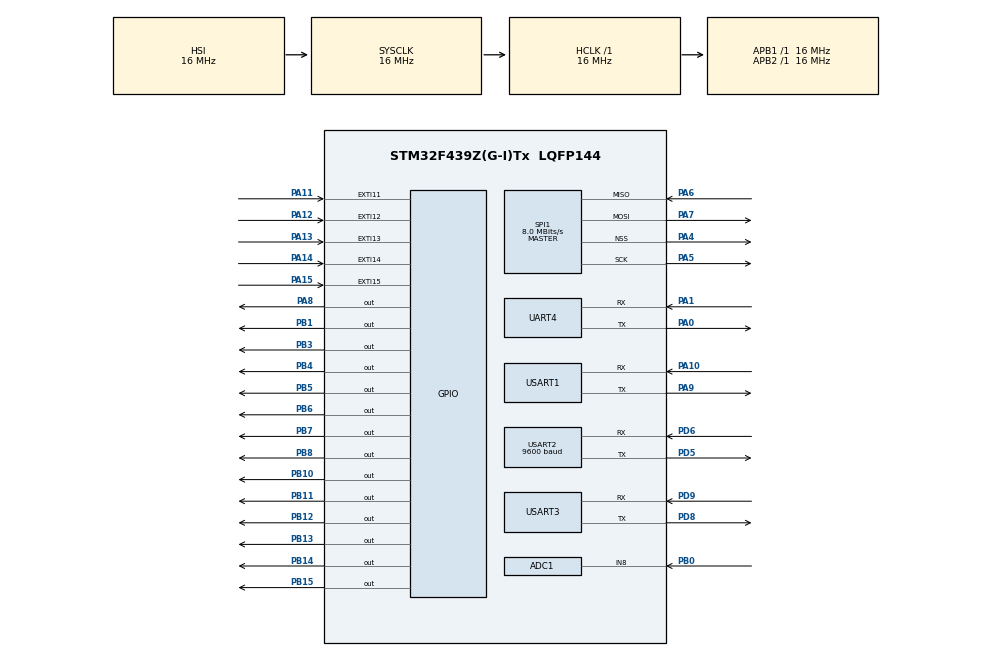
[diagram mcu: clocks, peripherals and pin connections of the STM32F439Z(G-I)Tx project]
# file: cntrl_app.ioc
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ADC1.Channel-0\#ChannelRegularConversion=ADC_CHANNEL_VBAT
ADC1.Channel-1\#ChannelRegularConversion=ADC_CHANNEL_8
ADC1.EOCSelection=ADC_EOC_SINGLE_CONV
ADC1.EnableAnalogWatchDog=false
ADC1.InjNumberOfConversion=0
ADC1.NbrOfConversion=2
ADC1.NbrOfConversionFlag=1
ADC1.Rank-0\#ChannelRegularConversion=1
ADC1.Rank-1\#ChannelRegularConversion=2
ADC1.SamplingTime-0\#ChannelRegularConversion=ADC_SAMPLETIME_3CYCLES
ADC1.SamplingTime-1\#ChannelRegularConversion=ADC_SAMPLETIME_3CYCLES
ADC1.master=1
Dma.Request0=SPI1_TX
Dma.Request1=SPI1_RX
Dma.SPI1_RX.1.Direction=DMA_PERIPH_TO_MEMORY
Dma.SPI1_RX.1.FIFOMode=DMA_FIFOMODE_ENABLE
Dma.SPI1_RX.1.FIFOThreshold=DMA_FIFO_THRESHOLD_FULL
Dma.SPI1_RX.1.Instance=DMA2_Stream0
Dma.SPI1_RX.1.MemBurst=DMA_MBURST_SINGLE
Dma.SPI1_RX.1.MemDataAlignment=DMA_MDATAALIGN_BYTE
Dma.SPI1_RX.1.MemInc=DMA_MINC_ENABLE
Dma.SPI1_RX.1.Mode=DMA_NORMAL
Dma.SPI1_RX.1.PeriphBurst=DMA_PBURST_SINGLE
Dma.SPI1_RX.1.PeriphDataAlignment=DMA_PDATAALIGN_BYTE
Dma.SPI1_RX.1.PeriphInc=DMA_PINC_DISABLE
Dma.SPI1_RX.1.Priority=DMA_PRIORITY_LOW
Dma.SPI1_TX.0.Direction=DMA_MEMORY_TO_PERIPH
Dma.SPI1_TX.0.FIFOMode=DMA_FIFOMODE_ENABLE
Dma.SPI1_TX.0.FIFOThreshold=DMA_FIFO_THRESHOLD_FULL
Dma.SPI1_TX.0.Instance=DMA2_Stream3
Dma.SPI1_TX.0.MemBurst=DMA_MBURST_SINGLE
Dma.SPI1_TX.0.MemDataAlignment=DMA_MDATAALIGN_BYTE
Dma.SPI1_TX.0.MemInc=DMA_MINC_ENABLE
Dma.SPI1_TX.0.Mode=DMA_NORMAL
Dma.SPI1_TX.0.PeriphBurst=DMA_PBURST_SINGLE
Dma.SPI1_TX.0.PeriphDataAlignment=DMA_PDATAALIGN_BYTE
Dma.SPI1_TX.0.PeriphInc=DMA_PINC_DISABLE
Dma.SPI1_TX.0.Priority=DMA_PRIORITY_LOW
Mcu.Family=STM32F4
Mcu.Name=STM32F439Z(G-I)Tx
Mcu.Package=LQFP144
NVIC.DMA2_Stream0_IRQn=true\:1\:0\:true\:false\:true\:false\:true
NVIC.DMA2_Stream3_IRQn=true\:1\:0\:true\:false\:true\:false\:true
NVIC.EXTI15_10_IRQn=true\:1\:0\:true\:false\:true\:true\:true
NVIC.PriorityGroup=NVIC_PRIORITYGROUP_4
NVIC.RTC_Alarm_IRQn=true\:1\:0\:true\:false\:true\:true\:true
NVIC.UART4_IRQn=true\:0\:0\:false\:false\:true\:true\:true
NVIC.USART2_IRQn=true\:0\:0\:true\:false\:true\:true\:true
PA0/WKUP.Mode=Asynchronous
PA0/WKUP.Signal=UART4_TX
PA1.Mode=Asynchronous
PA1.Signal=UART4_RX
PA10.Mode=Asynchronous
PA10.Signal=USART1_RX
PA11.GPIO_ModeDefaultEXTI=GPIO_MODE_IT_RISING_FALLING
PA11.Signal=GPXTI11
PA12.GPIO_ModeDefaultEXTI=GPIO_MODE_IT_RISING_FALLING
PA12.Signal=GPXTI12
PA13.GPIO_ModeDefaultEXTI=GPIO_MODE_IT_RISING_FALLING
PA13.Signal=GPXTI13
PA14.GPIO_ModeDefaultEXTI=GPIO_MODE_IT_RISING_FALLING
PA14.Signal=GPXTI14
PA15.GPIO_ModeDefaultEXTI=GPIO_MODE_IT_RISING_FALLING
PA15.Signal=GPXTI15
PA4.GPIO_PuPd=GPIO_PULLUP
PA4.GPIO_Speed=GPIO_SPEED_FREQ_VERY_HIGH
PA4.Mode=NSS_Signal_Hard_Output
PA4.Signal=SPI1_NSS
PA5.GPIO_Speed=GPIO_SPEED_FREQ_VERY_HIGH
PA5.Mode=Full_Duplex_Master
PA5.Signal=SPI1_SCK
PA6.Mode=Full_Duplex_Master
PA6.Signal=SPI1_MISO
PA7.Mode=Full_Duplex_Master
PA7.Signal=SPI1_MOSI
PA8.Signal=GPIO_Output
PA9.Mode=Asynchronous
PA9.Signal=USART1_TX
PB0.Signal=ADCx_IN8
PB1.Signal=GPIO_Output
PB10.Signal=GPIO_Output
PB11.Signal=GPIO_Output
PB12.Signal=GPIO_Output
PB13.Signal=GPIO_Output
PB14.Signal=GPIO_Output
PB15.Signal=GPIO_Output
PB3.Signal=GPIO_Output
PB4.Signal=GPIO_Output
PB5.Signal=GPIO_Output
PB6.Signal=GPIO_Output
PB7.Signal=GPIO_Output
PB8.Signal=GPIO_Output
PC14/OSC32_IN.Mode=LSE-External-Oscillator
PC14/OSC32_IN.Signal=RCC_OSC32_IN
PC15/OSC32_OUT.Mode=LSE-External-Oscillator
PC15/OSC32_OUT.Signal=RCC_OSC32_OUT
PD5.Mode=Asynchronous
PD5.Signal=USART2_TX
PD6.Mode=Asynchronous
PD6.Signal=USART2_RX
PD8.Mode=Asynchronous
PD8.Signal=USART3_TX
PD9.Mode=Asynchronous
PD9.Signal=USART3_RX
ProjectManager.HeapSize=0x200
ProjectManager.StackSize=0x400
ProjectManager.TargetToolchain=STM32CubeIDE
RCC.AHBFreq_Value=16000000
RCC.APB1Freq_Value=16000000
RCC.APB2Freq_Value=16000000
RCC.CortexFreq_Value=16000000
RCC.HSE_VALUE=25000000
RCC.HSI_VALUE=16000000
RCC.RCC_RTC_Clock_Source=RCC_RTCCLKSOURCE_LSE
RCC.RCC_RTC_Clock_SourceVirtual=RCC_RTCCLKSOURCE_LSE
RCC.SYSCLKFreq_VALUE=16000000
RCC.VCOOutputFreq_Value=192000000
RTC.Alarm=RTC_ALARM_A
RTC.Alarm_B=RTC_ALARM_B
SH.ADCx_IN8.0=ADC1_IN8,IN8
SPI1.BaudRatePrescaler=SPI_BAUDRATEPRESCALER_2
SPI1.CalculateBaudRate=8.0 MBits/s
SPI1.Direction=SPI_DIRECTION_2LINES
SPI1.Mode=SPI_MODE_MASTER
SPI1.VirtualNSS=VM_NSSHARD
SPI1.VirtualType=VM_MASTER
UART4.VirtualMode=Asynchronous
USART1.VirtualMode=VM_ASYNC
USART2.BaudRate=9600
USART2.VirtualMode=VM_ASYNC
USART3.VirtualMode=VM_ASYNC
VP_ADC1_Vbat_Input.Mode=IN-Vbat
VP_RTC_VS_RTC_Activate.Mode=RTC_Enabled
VP_RTC_VS_RTC_Alarm_A_Intern.Mode=Alarm A
VP_RTC_VS_RTC_Alarm_B_Intern.Mode=Alarm B
VP_RTC_VS_RTC_Calendar.Mode=RTC_Calendar
board=custom

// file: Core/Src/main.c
/* USER CODE BEGIN Header */
/**
  ******************************************************************************
  * @file           : main.c
  * @brief          : Main program body
  ******************************************************************************
  * @attention
  *
  * <h2><center>&copy; Copyright (c) 2020 STMicroelectronics.
  * All rights reserved.</center></h2>
  *
  * This software component is licensed by ST under BSD 3-Clause license,
  * the "License"; You may not use this file except in compliance with the
  * License. You may obtain a copy of the License at:
  *                        opensource.org/licenses/BSD-3-Clause
  *
  ******************************************************************************
  */
/* USER CODE END Header */

#include "main.h"

/* USER CODE BEGIN Includes */
#include "app.h"

/* USER CODE END Includes */

ADC_HandleTypeDef hadc1;

RTC_HandleTypeDef hrtc;

SPI_HandleTypeDef hspi1;
DMA_HandleTypeDef hdma_spi1_tx;
DMA_HandleTypeDef hdma_spi1_rx;

UART_HandleTypeDef huart4;
UART_HandleTypeDef huart1;
UART_HandleTypeDef huart2;
UART_HandleTypeDef huart3;

void SystemClock_Config(void);
static void MX_GPIO_Init(void);
static void MX_DMA_Init(void);
static void MX_RTC_Init(void);
static void MX_USART2_UART_Init(void);
static void MX_USART3_UART_Init(void);
static void MX_ADC1_Init(void);
static void MX_UART4_Init(void);
static void MX_USART1_UART_Init(void);
static void MX_SPI1_Init(void);

/* USER CODE BEGIN 0 */

extern volatile int XYZ ;
/* USER CODE END 0 */

int main(void)
{

  /* MCU Configuration--------------------------------------------------------*/

  /* Reset of all peripherals, Initializes the Flash interface and the Systick. */
  HAL_Init();

  /* Configure the system clock */
  SystemClock_Config();

  /* Initialize all configured peripherals */
  MX_GPIO_Init();
  MX_DMA_Init();
  MX_RTC_Init();
  MX_USART2_UART_Init();
  MX_USART3_UART_Init();
  MX_ADC1_Init();
  MX_UART4_Init();
  MX_USART1_UART_Init();
  MX_SPI1_Init();
  /* USER CODE BEGIN 2 */
  APP_Start();
 // while(1);

//  printf("%s():- App Entry\n", __FUNCTION__);

//  NVIC_EnableIRQ(USART3_IRQn | SVCall_IRQn |  PendSV_IRQn | SysTick_IRQn | USART2_IRQn);

  //   __HAL_UART_ENABLE_IT(&huart3,UART_IT_RXNE);

  //   XYZ = 12;

  /* USER CODE END 2 */

  /* Infinite loop */
  while (1)
  {

  }
}

void SystemClock_Config(void)
{
  RCC_OscInitTypeDef RCC_OscInitStruct = {0};
  RCC_ClkInitTypeDef RCC_ClkInitStruct = {0};
  RCC_PeriphCLKInitTypeDef PeriphClkInitStruct = {0};

  /** Configure the main internal regulator output voltage
  */
  __HAL_RCC_PWR_CLK_ENABLE();
  __HAL_PWR_VOLTAGESCALING_CONFIG(PWR_REGULATOR_VOLTAGE_SCALE3);
  /** Initializes the CPU, AHB and APB busses clocks
  */
  RCC_OscInitStruct.OscillatorType = RCC_OSCILLATORTYPE_HSI|RCC_OSCILLATORTYPE_LSE;
  RCC_OscInitStruct.LSEState = RCC_LSE_ON;
  RCC_OscInitStruct.HSIState = RCC_HSI_ON;
  RCC_OscInitStruct.HSICalibrationValue = RCC_HSICALIBRATION_DEFAULT;
  RCC_OscInitStruct.PLL.PLLState = RCC_PLL_NONE;
  if (HAL_RCC_OscConfig(&RCC_OscInitStruct) != HAL_OK)
  {
    Error_Handler();
  }
  /** Initializes the CPU, AHB and APB busses clocks
  */
  RCC_ClkInitStruct.ClockType = RCC_CLOCKTYPE_HCLK|RCC_CLOCKTYPE_SYSCLK
                              |RCC_CLOCKTYPE_PCLK1|RCC_CLOCKTYPE_PCLK2;
  RCC_ClkInitStruct.SYSCLKSource = RCC_SYSCLKSOURCE_HSI;
  RCC_ClkInitStruct.AHBCLKDivider = RCC_SYSCLK_DIV1;
  RCC_ClkInitStruct.APB1CLKDivider = RCC_HCLK_DIV1;
  RCC_ClkInitStruct.APB2CLKDivider = RCC_HCLK_DIV1;

  if (HAL_RCC_ClockConfig(&RCC_ClkInitStruct, FLASH_LATENCY_0) != HAL_OK)
  {
    Error_Handler();
  }
  PeriphClkInitStruct.PeriphClockSelection = RCC_PERIPHCLK_RTC;
  PeriphClkInitStruct.RTCClockSelection = RCC_RTCCLKSOURCE_LSE;
  if (HAL_RCCEx_PeriphCLKConfig(&PeriphClkInitStruct) != HAL_OK)
  {
    Error_Handler();
  }
}

static void MX_ADC1_Init(void)
{

  ADC_ChannelConfTypeDef sConfig = {0};

  /** Configure the global features of the ADC (Clock, Resolution, Data Alignment and number of conversion)
  */
  hadc1.Instance = ADC1;
  hadc1.Init.ClockPrescaler = ADC_CLOCK_SYNC_PCLK_DIV2;
  hadc1.Init.Resolution = ADC_RESOLUTION_12B;
  hadc1.Init.ScanConvMode = ENABLE;
  hadc1.Init.ContinuousConvMode = DISABLE;
  hadc1.Init.DiscontinuousConvMode = DISABLE;
  hadc1.Init.ExternalTrigConvEdge = ADC_EXTERNALTRIGCONVEDGE_NONE;
  hadc1.Init.ExternalTrigConv = ADC_SOFTWARE_START;
  hadc1.Init.DataAlign = ADC_DATAALIGN_RIGHT;
  hadc1.Init.NbrOfConversion = 2;
  hadc1.Init.DMAContinuousRequests = DISABLE;
  hadc1.Init.EOCSelection = ADC_EOC_SINGLE_CONV;
  if (HAL_ADC_Init(&hadc1) != HAL_OK)
  {
    Error_Handler();
  }
  /** Configure for the selected ADC regular channel its corresponding rank in the sequencer and its sample time.
  */
  sConfig.Channel = ADC_CHANNEL_VBAT;
  sConfig.Rank = 1;
  sConfig.SamplingTime = ADC_SAMPLETIME_3CYCLES;
  if (HAL_ADC_ConfigChannel(&hadc1, &sConfig) != HAL_OK)
  {
    Error_Handler();
  }
  /** Configure for the selected ADC regular channel its corresponding rank in the sequencer and its sample time.
  */
  sConfig.Channel = ADC_CHANNEL_8;
  sConfig.Rank = 2;
  if (HAL_ADC_ConfigChannel(&hadc1, &sConfig) != HAL_OK)
  {
    Error_Handler();
  }

}

static void MX_RTC_Init(void)
{

  RTC_TimeTypeDef sTime = {0};
  RTC_DateTypeDef sDate = {0};
  RTC_AlarmTypeDef sAlarm = {0};

  /** Initialize RTC Only
  */
  hrtc.Instance = RTC;
  hrtc.Init.HourFormat = RTC_HOURFORMAT_24;
  hrtc.Init.AsynchPrediv = 127;
  hrtc.Init.SynchPrediv = 255;
  hrtc.Init.OutPut = RTC_OUTPUT_DISABLE;
  hrtc.Init.OutPutPolarity = RTC_OUTPUT_POLARITY_HIGH;
  hrtc.Init.OutPutType = RTC_OUTPUT_TYPE_OPENDRAIN;
  if (HAL_RTC_Init(&hrtc) != HAL_OK)
  {
    Error_Handler();
  }

  /** Initialize RTC and set the Time and Date
  */
  sTime.Hours = 0x0;
  sTime.Minutes = 0x0;
  sTime.Seconds = 0x0;
  sTime.DayLightSaving = RTC_DAYLIGHTSAVING_NONE;
  sTime.StoreOperation = RTC_STOREOPERATION_RESET;
  if (HAL_RTC_SetTime(&hrtc, &sTime, RTC_FORMAT_BCD) != HAL_OK)
  {
    Error_Handler();
  }
  sDate.WeekDay = RTC_WEEKDAY_MONDAY;
  sDate.Month = RTC_MONTH_JANUARY;
  sDate.Date = 0x1;
  sDate.Year = 0x0;

  if (HAL_RTC_SetDate(&hrtc, &sDate, RTC_FORMAT_BCD) != HAL_OK)
  {
    Error_Handler();
  }
  /** Enable the Alarm A
  */
  sAlarm.AlarmTime.Hours = 0x0;
  sAlarm.AlarmTime.Minutes = 0x0;
  sAlarm.AlarmTime.Seconds = 0x0;
  sAlarm.AlarmTime.SubSeconds = 0x0;
  sAlarm.AlarmTime.DayLightSaving = RTC_DAYLIGHTSAVING_NONE;
  sAlarm.AlarmTime.StoreOperation = RTC_STOREOPERATION_RESET;
  sAlarm.AlarmMask = RTC_ALARMMASK_NONE;
  sAlarm.AlarmSubSecondMask = RTC_ALARMSUBSECONDMASK_ALL;
  sAlarm.AlarmDateWeekDaySel = RTC_ALARMDATEWEEKDAYSEL_DATE;
  sAlarm.AlarmDateWeekDay = 0x1;
  sAlarm.Alarm = RTC_ALARM_A;
  if (HAL_RTC_SetAlarm_IT(&hrtc, &sAlarm, RTC_FORMAT_BCD) != HAL_OK)
  {
    Error_Handler();
  }
  /** Enable the Alarm B
  */
  sAlarm.AlarmDateWeekDay = 0x1;
  sAlarm.Alarm = RTC_ALARM_B;
  if (HAL_RTC_SetAlarm_IT(&hrtc, &sAlarm, RTC_FORMAT_BCD) != HAL_OK)
  {
    Error_Handler();
  }

}

static void MX_SPI1_Init(void)
{

  /* SPI1 parameter configuration*/
  hspi1.Instance = SPI1;
  hspi1.Init.Mode = SPI_MODE_MASTER;
  hspi1.Init.Direction = SPI_DIRECTION_2LINES;
  hspi1.Init.DataSize = SPI_DATASIZE_8BIT;
  hspi1.Init.CLKPolarity = SPI_POLARITY_LOW;
  hspi1.Init.CLKPhase = SPI_PHASE_1EDGE;
  hspi1.Init.NSS = SPI_NSS_HARD_OUTPUT;
  hspi1.Init.BaudRatePrescaler = SPI_BAUDRATEPRESCALER_2;
  hspi1.Init.FirstBit = SPI_FIRSTBIT_MSB;
  hspi1.Init.TIMode = SPI_TIMODE_DISABLE;
  hspi1.Init.CRCCalculation = SPI_CRCCALCULATION_DISABLE;
  hspi1.Init.CRCPolynomial = 10;
  if (HAL_SPI_Init(&hspi1) != HAL_OK)
  {
    Error_Handler();
  }

}

static void MX_UART4_Init(void)
{

  huart4.Instance = UART4;
  huart4.Init.BaudRate = 115200;
  huart4.Init.WordLength = UART_WORDLENGTH_8B;
  huart4.Init.StopBits = UART_STOPBITS_1;
  huart4.Init.Parity = UART_PARITY_NONE;
  huart4.Init.Mode = UART_MODE_TX_RX;
  huart4.Init.HwFlowCtl = UART_HWCONTROL_NONE;
  huart4.Init.OverSampling = UART_OVERSAMPLING_16;
  if (HAL_UART_Init(&huart4) != HAL_OK)
  {
    Error_Handler();
  }

}

static void MX_USART1_UART_Init(void)
{

  huart1.Instance = USART1;
  huart1.Init.BaudRate = 115200;
  huart1.Init.WordLength = UART_WORDLENGTH_8B;
  huart1.Init.StopBits = UART_STOPBITS_1;
  huart1.Init.Parity = UART_PARITY_NONE;
  huart1.Init.Mode = UART_MODE_TX_RX;
  huart1.Init.HwFlowCtl = UART_HWCONTROL_NONE;
  huart1.Init.OverSampling = UART_OVERSAMPLING_16;
  if (HAL_UART_Init(&huart1) != HAL_OK)
  {
    Error_Handler();
  }

}

static void MX_USART2_UART_Init(void)
{

  huart2.Instance = USART2;
  huart2.Init.BaudRate = 9600;
  huart2.Init.WordLength = UART_WORDLENGTH_8B;
  huart2.Init.StopBits = UART_STOPBITS_1;
  huart2.Init.Parity = UART_PARITY_NONE;
  huart2.Init.Mode = UART_MODE_TX_RX;
  huart2.Init.HwFlowCtl = UART_HWCONTROL_NONE;
  huart2.Init.OverSampling = UART_OVERSAMPLING_16;
  if (HAL_UART_Init(&huart2) != HAL_OK)
  {
    Error_Handler();
  }

}

static void MX_USART3_UART_Init(void)
{

  huart3.Instance = USART3;
  huart3.Init.BaudRate = 115200;
  huart3.Init.WordLength = UART_WORDLENGTH_8B;
  huart3.Init.StopBits = UART_STOPBITS_1;
  huart3.Init.Parity = UART_PARITY_NONE;
  huart3.Init.Mode = UART_MODE_TX_RX;
  huart3.Init.HwFlowCtl = UART_HWCONTROL_NONE;
  huart3.Init.OverSampling = UART_OVERSAMPLING_16;
  if (HAL_UART_Init(&huart3) != HAL_OK)
  {
    Error_Handler();
  }

}

static void MX_DMA_Init(void)
{

  /* DMA controller clock enable */
  __HAL_RCC_DMA2_CLK_ENABLE();

  /* DMA interrupt init */
  /* DMA2_Stream0_IRQn interrupt configuration */
  HAL_NVIC_SetPriority(DMA2_Stream0_IRQn, 1, 0);
  HAL_NVIC_EnableIRQ(DMA2_Stream0_IRQn);
  /* DMA2_Stream3_IRQn interrupt configuration */
  HAL_NVIC_SetPriority(DMA2_Stream3_IRQn, 1, 0);
  HAL_NVIC_EnableIRQ(DMA2_Stream3_IRQn);

}

static void MX_GPIO_Init(void)
{
  GPIO_InitTypeDef GPIO_InitStruct = {0};

  /* GPIO Ports Clock Enable */
  __HAL_RCC_GPIOC_CLK_ENABLE();
  __HAL_RCC_GPIOA_CLK_ENABLE();
  __HAL_RCC_GPIOB_CLK_ENABLE();
  __HAL_RCC_GPIOD_CLK_ENABLE();

  /*Configure GPIO pin Output Level */
  HAL_GPIO_WritePin(GPIOB, GPIO_PIN_1|GPIO_PIN_10|GPIO_PIN_11|GPIO_PIN_12
                          |GPIO_PIN_13|GPIO_PIN_14|GPIO_PIN_15|GPIO_PIN_3
                          |GPIO_PIN_4|GPIO_PIN_5|GPIO_PIN_6|GPIO_PIN_7
                          |GPIO_PIN_8, GPIO_PIN_RESET);

  /*Configure GPIO pin Output Level */
  HAL_GPIO_WritePin(GPIOA, GPIO_PIN_8, GPIO_PIN_RESET);

  /*Configure GPIO pins : PB1 PB10 PB11 PB12
                           PB13 PB14 PB15 PB3
                           PB4 PB5 PB6 PB7
                           PB8 */
  GPIO_InitStruct.Pin = GPIO_PIN_1|GPIO_PIN_10|GPIO_PIN_11|GPIO_PIN_12
                          |GPIO_PIN_13|GPIO_PIN_14|GPIO_PIN_15|GPIO_PIN_3
                          |GPIO_PIN_4|GPIO_PIN_5|GPIO_PIN_6|GPIO_PIN_7
                          |GPIO_PIN_8;
  GPIO_InitStruct.Mode = GPIO_MODE_OUTPUT_PP;
  GPIO_InitStruct.Pull = GPIO_NOPULL;
  GPIO_InitStruct.Speed = GPIO_SPEED_FREQ_LOW;
  HAL_GPIO_Init(GPIOB, &GPIO_InitStruct);

  /*Configure GPIO pin : PA8 */
  GPIO_InitStruct.Pin = GPIO_PIN_8;
  GPIO_InitStruct.Mode = GPIO_MODE_OUTPUT_PP;
  GPIO_InitStruct.Pull = GPIO_NOPULL;
  GPIO_InitStruct.Speed = GPIO_SPEED_FREQ_LOW;
  HAL_GPIO_Init(GPIOA, &GPIO_InitStruct);

  /*Configure GPIO pins : PA11 PA12 PA13 PA14
                           PA15 */
  GPIO_InitStruct.Pin = GPIO_PIN_11|GPIO_PIN_12|GPIO_PIN_13|GPIO_PIN_14
                          |GPIO_PIN_15;
  GPIO_InitStruct.Mode = GPIO_MODE_IT_RISING_FALLING;
  GPIO_InitStruct.Pull = GPIO_NOPULL;
  HAL_GPIO_Init(GPIOA, &GPIO_InitStruct);

  /* EXTI interrupt init*/
  HAL_NVIC_SetPriority(EXTI15_10_IRQn, 1, 0);
  HAL_NVIC_EnableIRQ(EXTI15_10_IRQn);

}

/* USER CODE BEGIN 4 */

/*
int __io_putchar(int ch) {
  HAL_UART_Transmit(&huart3, (uint8_t *)&ch, 1, 0xFFFF);
  return ch;
} */

/* USER CODE END 4 */

void Error_Handler(void)
{
}

/************************ (C) COPYRIGHT STMicroelectronics *****END OF FILE****/
